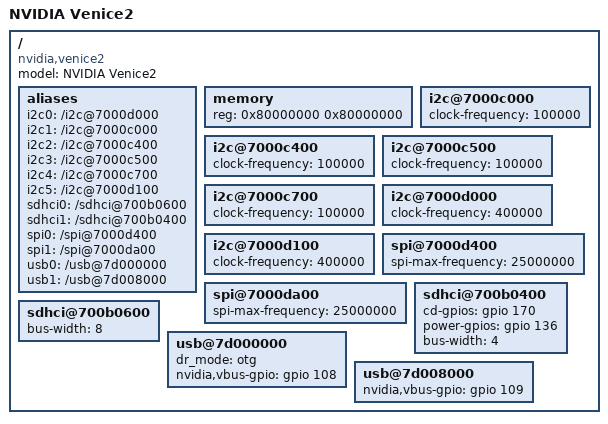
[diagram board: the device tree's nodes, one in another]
/dts-v1/;

#include "tegra124.dtsi"

/ {
	model = "NVIDIA Venice2";
	compatible = "nvidia,venice2", "nvidia,tegra124";

	aliases {
		i2c0 = "/i2c@7000d000";
		i2c1 = "/i2c@7000c000";
		i2c2 = "/i2c@7000c400";
		i2c3 = "/i2c@7000c500";
		i2c4 = "/i2c@7000c700";
		i2c5 = "/i2c@7000d100";
		sdhci0 = "/sdhci@700b0600";
		sdhci1 = "/sdhci@700b0400";
		spi0 = "/spi@7000d400";
		spi1 = "/spi@7000da00";
		usb0 = "/usb@7d000000";
		usb1 = "/usb@7d008000";
	};

	memory {
		device_type = "memory";
		reg = <0x80000000 0x80000000>;
	};

	i2c@7000c000 {
		status = "okay";
		clock-frequency = <100000>;
	};

	i2c@7000c400 {
		status = "okay";
		clock-frequency = <100000>;
	};

	i2c@7000c500 {
		status = "okay";
		clock-frequency = <100000>;
	};

	i2c@7000c700 {
		status = "okay";
		clock-frequency = <100000>;
	};

	i2c@7000d000 {
		status = "okay";
		clock-frequency = <400000>;
	};

	i2c@7000d100 {
		status = "okay";
		clock-frequency = <400000>;
	};

	spi@7000d400 {
		status = "okay";
		spi-max-frequency = <25000000>;
	};

	spi@7000da00 {
		status = "okay";
		spi-max-frequency = <25000000>;
	};

	sdhci@700b0400 {
		status = "okay";
		cd-gpios = <&gpio 170 0>; /* gpio PV2 */
		power-gpios = <&gpio 136 0>; /* gpio PR0 */
		bus-width = <4>;
	};

	sdhci@700b0600 {
		status = "okay";
		bus-width = <8>;
	};

	usb@7d000000 {
		status = "okay";
		dr_mode = "otg";
		nvidia,vbus-gpio = <&gpio 108 0>; /* gpio PN4, USB_VBUS_EN0 */
	};

	usb@7d008000 {
		status = "okay";
		nvidia,vbus-gpio = <&gpio 109 0>; /* gpio PN5, USB_VBUS_EN1 */
	};
};
